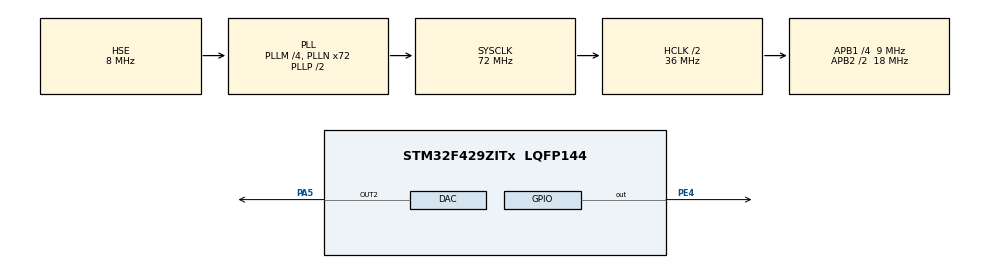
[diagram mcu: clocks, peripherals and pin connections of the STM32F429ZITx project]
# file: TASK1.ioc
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DAC.DAC_OutputBuffer2=DAC_OUTPUTBUFFER_DISABLE
DAC.DAC_Trigger2=DAC_TRIGGER_NONE
Mcu.Family=STM32F4
Mcu.Name=STM32F429ZITx
Mcu.Package=LQFP144
NVIC.PriorityGroup=NVIC_PRIORITYGROUP_4
NVIC.TIM5_IRQn=true\:0\:0\:false\:false\:true\:true\:true
PA5.Signal=COMP_DAC2_group
PE4.GPIO_Speed=GPIO_SPEED_FREQ_VERY_HIGH
PE4.Signal=GPIO_Output
PH0/OSC_IN.Mode=HSE-External-Oscillator
PH0/OSC_IN.Signal=RCC_OSC_IN
PH1/OSC_OUT.Mode=HSE-External-Oscillator
PH1/OSC_OUT.Signal=RCC_OSC_OUT
ProjectManager.HeapSize=0x200
ProjectManager.StackSize=0x400
ProjectManager.TargetToolchain=EWARM V8.32
RCC.48MHZClocksFreq_Value=36000000
RCC.AHBCLKDivider=RCC_SYSCLK_DIV2
RCC.AHBFreq_Value=36000000
RCC.APB1CLKDivider=RCC_HCLK_DIV4
RCC.APB1Freq_Value=9000000
RCC.APB1TimFreq_Value=18000000
RCC.APB2CLKDivider=RCC_HCLK_DIV2
RCC.APB2Freq_Value=18000000
RCC.APB2TimFreq_Value=36000000
RCC.CortexFreq_Value=36000000
RCC.HCLKFreq_Value=36000000
RCC.HSE_VALUE=8000000
RCC.HSI_VALUE=16000000
RCC.LSE_VALUE=32768
RCC.PLLM=4
RCC.PLLN=72
RCC.PLLSourceVirtual=RCC_PLLSOURCE_HSE
RCC.SYSCLKFreq_VALUE=72000000
RCC.SYSCLKSource=RCC_SYSCLKSOURCE_PLLCLK
RCC.VCOOutputFreq_Value=144000000
SH.COMP_DAC2_group.0=DAC_OUT2,DAC_OUT2
TIM5.Period=719
VP_TIM5_VS_ClockSourceINT.Mode=Internal
board=custom

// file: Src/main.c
/* USER CODE BEGIN Header */
/**
  ******************************************************************************
  * @file           : main.c
  * @brief          : Main program body
  ******************************************************************************
  * @attention
  *
  * <h2><center>&copy; Copyright (c) 2020 STMicroelectronics.
  * All rights reserved.</center></h2>
  *
  * This software component is licensed by ST under BSD 3-Clause license,
  * the "License"; You may not use this file except in compliance with the
  * License. You may obtain a copy of the License at:
  *                        opensource.org/licenses/BSD-3-Clause
  *
  ******************************************************************************
  */
/* USER CODE END Header */

#include "main.h"

DAC_HandleTypeDef hdac;

TIM_HandleTypeDef htim5;

/* USER CODE BEGIN PV */
uint16_t dataArray[1024];
/* USER CODE END PV */

void SystemClock_Config(void);
static void MX_GPIO_Init(void);
static void MX_DAC_Init(void);
static void MX_TIM5_Init(void);

int main(void)
{
  /* USER CODE BEGIN 1 */
for ( uint16_t i = 0; i < 1024; i = i + 1 ) {
    dataArray[i] = i * 4;
  }
  /* USER CODE END 1 */

  /* MCU Configuration--------------------------------------------------------*/

  /* Reset of all peripherals, Initializes the Flash interface and the Systick. */
  HAL_Init();

  /* Configure the system clock */
  SystemClock_Config();

  /* Initialize all configured peripherals */
  MX_GPIO_Init();
  MX_DAC_Init();
  MX_TIM5_Init();
  /* USER CODE BEGIN 2 */
HAL_DAC_Start(&hdac, DAC_CHANNEL_2);
HAL_TIM_Base_Start_IT(&htim5);
  /* USER CODE END 2 */

  /* Infinite loop */
  while (1)
  {

  }
}

void SystemClock_Config(void)
{
  RCC_OscInitTypeDef RCC_OscInitStruct = {0};
  RCC_ClkInitTypeDef RCC_ClkInitStruct = {0};

  /** Configure the main internal regulator output voltage
  */
  __HAL_RCC_PWR_CLK_ENABLE();
  __HAL_PWR_VOLTAGESCALING_CONFIG(PWR_REGULATOR_VOLTAGE_SCALE3);
  /** Initializes the CPU, AHB and APB busses clocks
  */
  RCC_OscInitStruct.OscillatorType = RCC_OSCILLATORTYPE_HSE;
  RCC_OscInitStruct.HSEState = RCC_HSE_ON;
  RCC_OscInitStruct.PLL.PLLState = RCC_PLL_ON;
  RCC_OscInitStruct.PLL.PLLSource = RCC_PLLSOURCE_HSE;
  RCC_OscInitStruct.PLL.PLLM = 4;
  RCC_OscInitStruct.PLL.PLLN = 72;
  RCC_OscInitStruct.PLL.PLLP = RCC_PLLP_DIV2;
  RCC_OscInitStruct.PLL.PLLQ = 4;
  if (HAL_RCC_OscConfig(&RCC_OscInitStruct) != HAL_OK)
  {
    Error_Handler();
  }
  /** Initializes the CPU, AHB and APB busses clocks
  */
  RCC_ClkInitStruct.ClockType = RCC_CLOCKTYPE_HCLK|RCC_CLOCKTYPE_SYSCLK
                              |RCC_CLOCKTYPE_PCLK1|RCC_CLOCKTYPE_PCLK2;
  RCC_ClkInitStruct.SYSCLKSource = RCC_SYSCLKSOURCE_PLLCLK;
  RCC_ClkInitStruct.AHBCLKDivider = RCC_SYSCLK_DIV2;
  RCC_ClkInitStruct.APB1CLKDivider = RCC_HCLK_DIV4;
  RCC_ClkInitStruct.APB2CLKDivider = RCC_HCLK_DIV2;

  if (HAL_RCC_ClockConfig(&RCC_ClkInitStruct, FLASH_LATENCY_1) != HAL_OK)
  {
    Error_Handler();
  }
}

static void MX_DAC_Init(void)
{

  DAC_ChannelConfTypeDef sConfig = {0};

  /** DAC Initialization
  */
  hdac.Instance = DAC;
  if (HAL_DAC_Init(&hdac) != HAL_OK)
  {
    Error_Handler();
  }
  /** DAC channel OUT2 config
  */
  sConfig.DAC_Trigger = DAC_TRIGGER_NONE;
  sConfig.DAC_OutputBuffer = DAC_OUTPUTBUFFER_DISABLE;
  if (HAL_DAC_ConfigChannel(&hdac, &sConfig, DAC_CHANNEL_2) != HAL_OK)
  {
    Error_Handler();
  }

}

static void MX_TIM5_Init(void)
{

  TIM_ClockConfigTypeDef sClockSourceConfig = {0};
  TIM_MasterConfigTypeDef sMasterConfig = {0};

  htim5.Instance = TIM5;
  htim5.Init.Prescaler = 0;
  htim5.Init.CounterMode = TIM_COUNTERMODE_UP;
  htim5.Init.Period = 719;
  htim5.Init.ClockDivision = TIM_CLOCKDIVISION_DIV1;
  htim5.Init.AutoReloadPreload = TIM_AUTORELOAD_PRELOAD_DISABLE;
  if (HAL_TIM_Base_Init(&htim5) != HAL_OK)
  {
    Error_Handler();
  }
  sClockSourceConfig.ClockSource = TIM_CLOCKSOURCE_INTERNAL;
  if (HAL_TIM_ConfigClockSource(&htim5, &sClockSourceConfig) != HAL_OK)
  {
    Error_Handler();
  }
  sMasterConfig.MasterOutputTrigger = TIM_TRGO_RESET;
  sMasterConfig.MasterSlaveMode = TIM_MASTERSLAVEMODE_DISABLE;
  if (HAL_TIMEx_MasterConfigSynchronization(&htim5, &sMasterConfig) != HAL_OK)
  {
    Error_Handler();
  }

}

static void MX_GPIO_Init(void)
{
  GPIO_InitTypeDef GPIO_InitStruct = {0};

  /* GPIO Ports Clock Enable */
  __HAL_RCC_GPIOE_CLK_ENABLE();
  __HAL_RCC_GPIOH_CLK_ENABLE();
  __HAL_RCC_GPIOA_CLK_ENABLE();

  /*Configure GPIO pin Output Level */
  HAL_GPIO_WritePin(GPIOE, GPIO_PIN_4, GPIO_PIN_RESET);

  /*Configure GPIO pin : PE4 */
  GPIO_InitStruct.Pin = GPIO_PIN_4;
  GPIO_InitStruct.Mode = GPIO_MODE_OUTPUT_PP;
  GPIO_InitStruct.Pull = GPIO_NOPULL;
  GPIO_InitStruct.Speed = GPIO_SPEED_FREQ_VERY_HIGH;
  HAL_GPIO_Init(GPIOE, &GPIO_InitStruct);

}

void Error_Handler(void)
{
}

/************************ (C) COPYRIGHT STMicroelectronics *****END OF FILE****/
